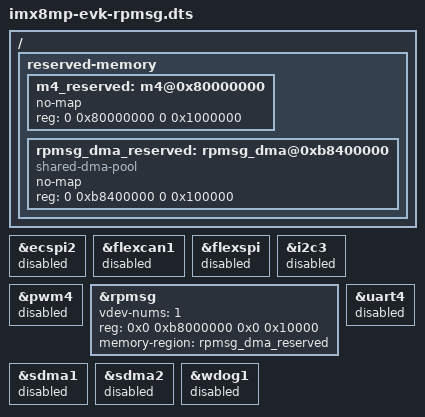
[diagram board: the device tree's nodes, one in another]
// SPDX-License-Identifier: (GPL-2.0 OR MIT)
/*
 * Copyright 2020 NXP
 */

/dts-v1/;

#include "imx8mp-evk.dts"

/ {
	reserved-memory {
		#address-cells = <2>;
		#size-cells = <2>;
		ranges;

		m4_reserved: m4@0x80000000 {
			no-map;
			reg = <0 0x80000000 0 0x1000000>;
		};

		rpmsg_dma_reserved:rpmsg_dma@0xb8400000 {
			compatible = "shared-dma-pool";
			no-map;
			reg = <0 0xb8400000 0 0x100000>;
		};
	};
};

/*
 * ATTENTION: M7 may use IPs like below
 * ECSPI0/ECSPI2, FLEXCAN, GPIO1/GPIO5, GPT1, I2C3, I2S3, WDOG1, UART4,
 * PWM4, SDMA1/SDMA2
 */
&ecspi2 {
	status = "disabled";
};

&flexcan1 {
	status = "disabled";
};

&flexspi {
	status = "disabled";
};

&i2c3 {
	status = "disabled";
};

&pwm4{
	status = "disabled";
};

&rpmsg{
	/*
	 * 64K for one rpmsg instance:
	 * --0xb8000000~0xb800ffff: pingpong
	 */
	vdev-nums = <1>;
	reg = <0x0 0xb8000000 0x0 0x10000>;
	memory-region = <&rpmsg_dma_reserved>;
	status = "okay";
};

&sdma1{
	status = "disabled";
};

&sdma2{
	status = "disabled";
};

&uart4 {
	status = "disabled";
};

&wdog1 {
	status = "disabled";
};
